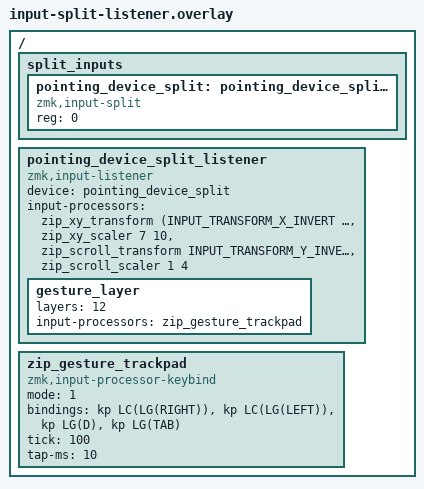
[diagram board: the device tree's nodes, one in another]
#include <dt-bindings/zmk/keys.h>
#include <dt-bindings/zmk/modifiers.h>

/{
    split_inputs {
        #address-cells = <1>;
        #size-cells = <0>;

        pointing_device_split: pointing_device_split@0 {
            compatible = "zmk,input-split";
            reg = <0>;
        };
    };

    pointing_device_split_listener: pointing_device_split_listener {
        compatible = "zmk,input-listener";
        device = <&pointing_device_split>;
        status = "okay";
        input-processors =
            <&zip_xy_transform (INPUT_TRANSFORM_X_INVERT | INPUT_TRANSFORM_Y_INVERT)>,
            <&zip_xy_scaler 7 10>,
            <&zip_scroll_transform INPUT_TRANSFORM_Y_INVERT>,
            <&zip_scroll_scaler 1 4>;
    };
};

/* === keymap-editor: gesture config (auto-generated, safe to regenerate) === */
/ {
    zip_gesture_trackpad: zip_gesture_trackpad {
        compatible = "zmk,input-processor-keybind";
        #input-processor-cells = <0>;
        mode = <1>;
        bindings = <&kp LC(LG(RIGHT))>, <&kp LC(LG(LEFT))>, <&kp LG(D)>, <&kp LG(TAB)>;
        tick = <100>;
        tap-ms = <10>;
    };
};

&pointing_device_split_listener {
    gesture_layer {
        layers = <12>;
        input-processors = <&zip_gesture_trackpad>;
    };
};
/* === keymap-editor: end gesture config === */
